# CW32L031 register map
Vendor: Wuhan Xinyuan Semiconductor Co.,Ltd; Series: CW32L03xx; File version: 1.2
CPU: CM0+ r0p1, little endian, no MPU, no FPU, 3 interrupt priority bits
Registers are 32-bit, read-write, no defined reset value unless marked. A register's access mark holds for its fields unless they carry their own. Offsets are from the block's base; [hi:lo] are bit positions; {n}, {i} and the like mark numbered series; 'fields as' and 'values as' point back to an identical list.

## GTIM1 — General Timer 1
Base 0x40000400
Same registers: GTIM2 0x40001000, GTIM3 0x40014000, GTIM4 0x40014400
0x300 ARR — Auto Reload Register
  [15:0] ARR
0x304 CNT — Counter Register
  [15:0] CNT
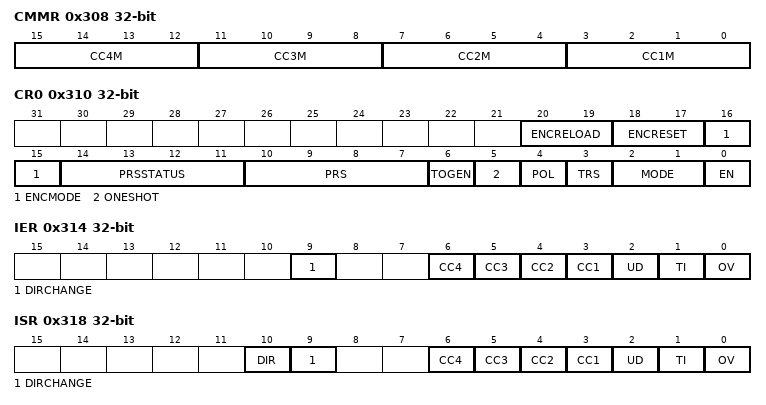
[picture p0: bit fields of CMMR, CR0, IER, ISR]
0x308 CMMR — Capture compare control Register
  [4n-1:4n-4] CC{n}M (n=1..4)
0x30C ETR — ETR Control register
  [6:4] ETRFLT
0x310 CR0 — Control register0
  [20:19] ENCRELOAD, [18:17] ENCRESET, [16:15] ENCMODE, [14:11] PRSSTATUS ro, [10:7] PRS, [6] TOGEN, [5] ONESHOT, [4] POL, [3] TRS, [2:1] MODE, [0] EN
0x314 IER — Interrupt enable register
  [9] DIRCHANGE, [n+2] CC{n} (n=1..4), [2] UD, [1] TI, [0] OV
0x318 ISR — Interrupt status register
  [10] DIR ro, [9] DIRCHANGE ro, [n+2] CC{n} ro (n=1..4), [2] UD, [1] TI, [0] OV
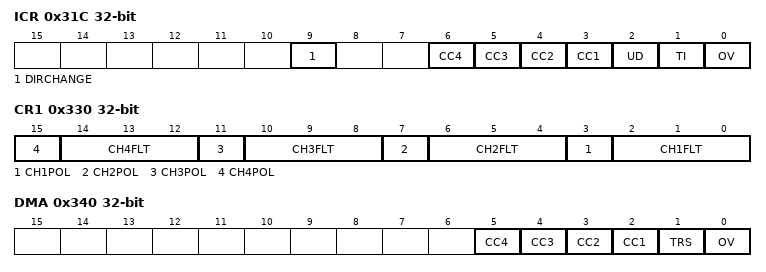
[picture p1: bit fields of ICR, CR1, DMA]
0x31C ICR — Interrupt flag clear register
  [9] DIRCHANGE, [n+2] CC{n} (n=1..4), [2] UD, [1] TI, [0] OV
{0x31C+4i} CCR{i} (i=1..4) — capture compare register
  [15:0] CCR
0x330 CR1 — Control register1
  [4n-1] CH{n}POL (n=1..4), [4n-2:4n-4] CH{n}FLT (n=1..4)
0x340 DMA — DMA Control register
  [n+1] CC{n} (n=1..4), [1] TRS, [0] OV

## I2C1
Base 0x40005400
Same registers: I2C2 0x40005800
0x00 BRREN
  [0] EN
0x04 BRR
  [7:0] BRR — fSCL = fPCLK / 8 / (BRR+1)
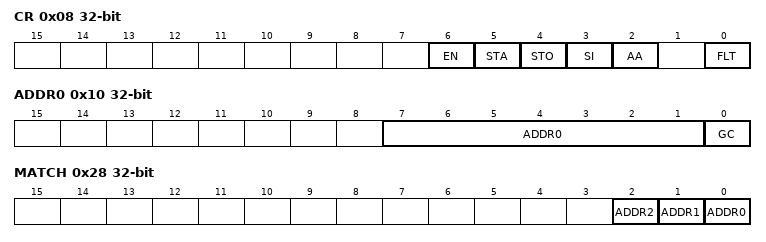
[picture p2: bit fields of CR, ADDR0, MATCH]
0x08 CR — Control register
  [6] EN, [5] STA, [4] STO, [3] SI, [2] AA, [0] FLT
0x0C DR — Data register
  [7:0] DR
0x10 ADDR0 — Slave Addrress0
  [7:1] ADDR0, [0] GC
0x14 STAT ro — Status register
  [7:0] STAT
0x20 ADDR1 — Slave Addrress1
  [7:1] ADDR1
0x24 ADDR2 — Slave Addrress2
  [7:1] ADDR2
0x28 MATCH ro — Slave Addrress match flag
  [2] ADDR2, [1] ADDR1, [0] ADDR0

## IWDT
Base 0x40003000
0x00 KR wo — Key register
  [15:0] KR
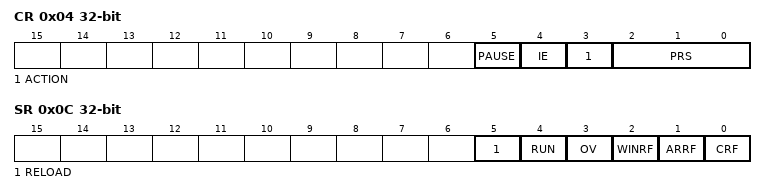
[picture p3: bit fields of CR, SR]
0x04 CR — Control register
  [5] PAUSE, [4] IE, [3] ACTION, [2:0] PRS
0x08 ARR — Auto reload register
  [11:0] ARR
0x0C SR — Status register
  [5] RELOAD ro, [4] RUN ro, [3] OV, [2] WINRF ro, [1] ARRF ro, [0] CRF ro
0x10 WINR — Window register
  [11:0] WINR
0x24 CNT ro — counter
  [11:0] CNT

## LVD
Base 0x40012A80
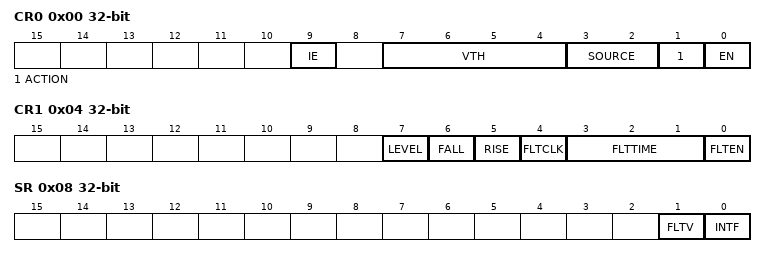
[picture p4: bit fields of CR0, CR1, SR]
0x00 CR0 — Control register0
  [9] IE, [7:4] VTH, [3:2] SOURCE, [1] ACTION, [0] EN
0x04 CR1 — Control register1
  [7] LEVEL, [6] FALL, [5] RISE, [4] FLTCLK, [3:1] FLTTIME, [0] FLTEN
0x08 SR — status register
  [1] FLTV ro, [0] INTF

## RAM
Base 0x40022400
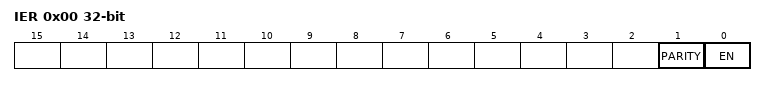
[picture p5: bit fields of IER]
0x00 IER — Interrupt enable register
  [1] PARITY, [0] EN
0x04 ADDR ro — Parity check error addr register
0x08 ISR ro — Interrupt flag register
  [0] PARITY
0x0C ICR — Interrupt flag clear register
  [0] PARITY

## RTC
Base 0x40002800
0x00 KEY wo
  [7:0] KEY — Key = 0xCA - 0x53
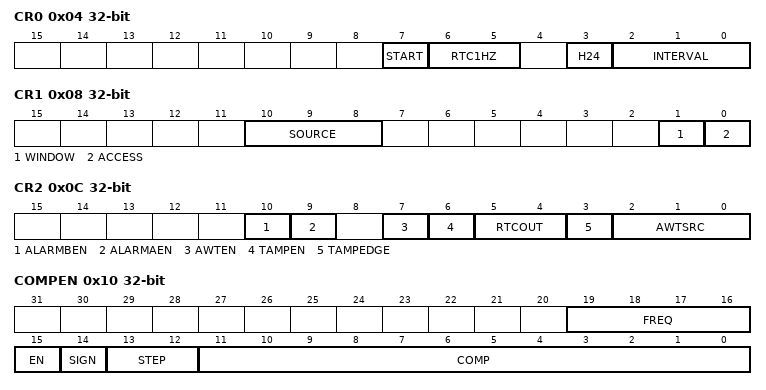
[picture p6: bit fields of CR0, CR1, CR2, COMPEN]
0x04 CR0 — Control register0
  [7] START, [6:5] RTC1HZ, [3] H24, [2:0] INTERVAL
0x08 CR1 — Control register1
  [10:8] SOURCE, [1] WINDOW ro, [0] ACCESS
0x0C CR2 — Control register2
  [10] ALARMBEN, [9] ALARMAEN, [7] AWTEN, [6] TAMPEN, [5:4] RTCOUT, [3] TAMPEDGE, [2:0] AWTSRC
0x10 COMPEN
  [19:16] FREQ, [15] EN, [14] SIGN, [13:12] STEP, [11:0] COMP
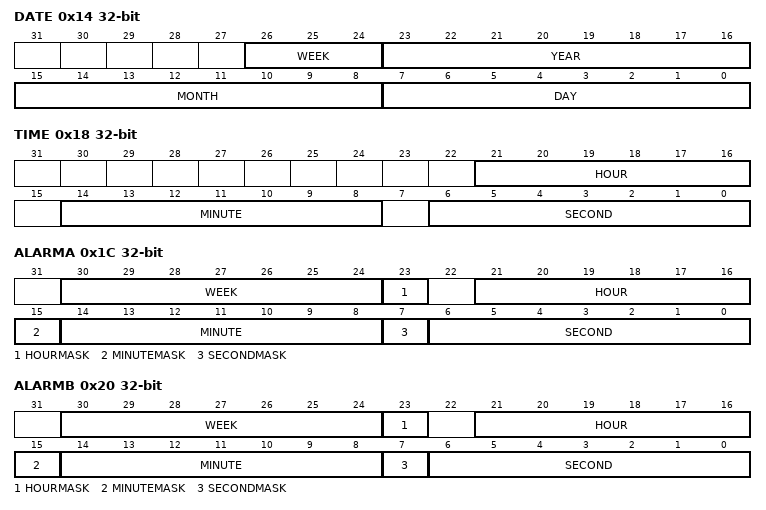
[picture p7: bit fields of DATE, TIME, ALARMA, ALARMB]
0x14 DATE — Time.Second register
  [26:24] WEEK, [23:16] YEAR, [15:8] MONTH, [7:0] DAY
0x18 TIME — Time.Second register
  [21:16] HOUR, [14:8] MINUTE, [6:0] SECOND
0x1C ALARMA
  [30:24] WEEK, [23] HOURMASK, [21:16] HOUR, [15] MINUTEMASK, [14:8] MINUTE, [7] SECONDMASK, [6:0] SECOND
0x20 ALARMB
  fields as ALARMA
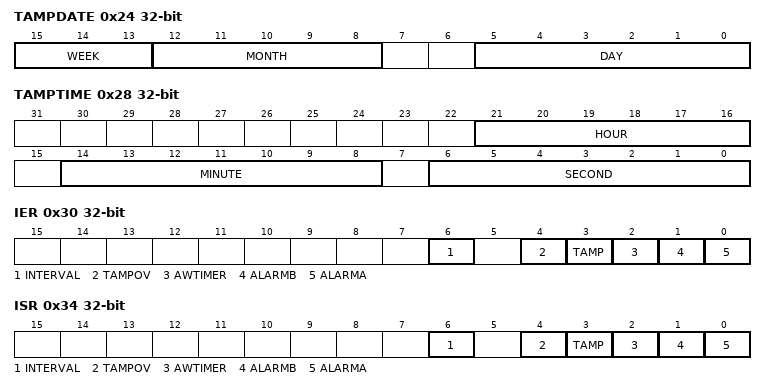
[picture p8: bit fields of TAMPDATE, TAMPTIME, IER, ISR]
0x24 TAMPDATE
  [15:13] WEEK, [12:8] MONTH, [5:0] DAY
0x28 TAMPTIME
  [21:16] HOUR, [14:8] MINUTE, [6:0] SECOND
0x2C AWTARR — Auto Wakeup Timer Auto Reload Register
  [15:0] ARR
0x30 IER — Interrupt enable register
  [6] INTERVAL, [4] TAMPOV, [3] TAMP, [2] AWTIMER, [1] ALARMB, [0] ALARMA
0x34 ISR ro — Interrupt status register
  fields as IER
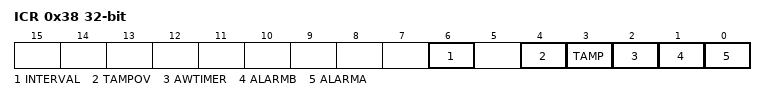
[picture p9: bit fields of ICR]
0x38 ICR — Interrupt flag clear register
  fields as IER
